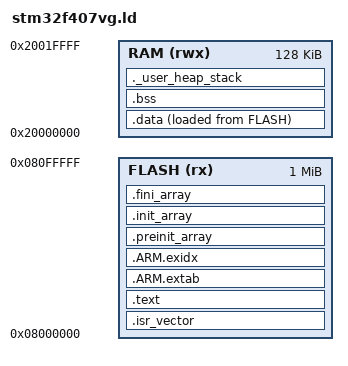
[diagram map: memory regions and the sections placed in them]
ENTRY(Reset_Handler)

MEMORY
{
    FLASH (rx) : ORIGIN = 0x08000000, LENGTH = 1024K
    RAM (rwx)  : ORIGIN = 0x20000000, LENGTH = 128K
}

_estack = ORIGIN(RAM) + LENGTH(RAM);

SECTIONS
{
    .isr_vector :
    {
        KEEP(*(.isr_vector))
    } > FLASH

    .text :
    {
        *(.text*)
        *(.rodata*)
        . = ALIGN(4);
    } > FLASH

    .ARM.extab :
    {
        *(.ARM.extab*)
    } > FLASH

    .ARM.exidx :
    {
        __exidx_start = .;
        *(.ARM.exidx*)
        __exidx_end = .;
    } > FLASH

    .preinit_array :
    {
        . = ALIGN(4);
        __preinit_array_start = .;
        KEEP(*(.preinit_array*))
        __preinit_array_end = .;
    } > FLASH

    .init_array :
    {
        . = ALIGN(4);
        __init_array_start = .;
        KEEP(*(.init_array*))
        __init_array_end = .;
    } > FLASH

    .fini_array :
    {
        . = ALIGN(4);
        __fini_array_start = .;
        KEEP(*(.fini_array*))
        __fini_array_end = .;
    } > FLASH

    _sidata = LOADADDR(.data);

    .data :
    {
        . = ALIGN(4);
        _sdata = .;
        *(.data*)
        . = ALIGN(4);
        _edata = .;
    } > RAM AT > FLASH

    .bss :
    {
        . = ALIGN(4);
        _sbss = .;
        *(.bss*)
        *(COMMON)
        . = ALIGN(4);
        _ebss = .;
    } > RAM

    ._user_heap_stack :
    {
        . = ALIGN(8);
        _end = .;
        PROVIDE(end = .);
        . = . + 0x800;
        . = ALIGN(8);
    } > RAM
}
